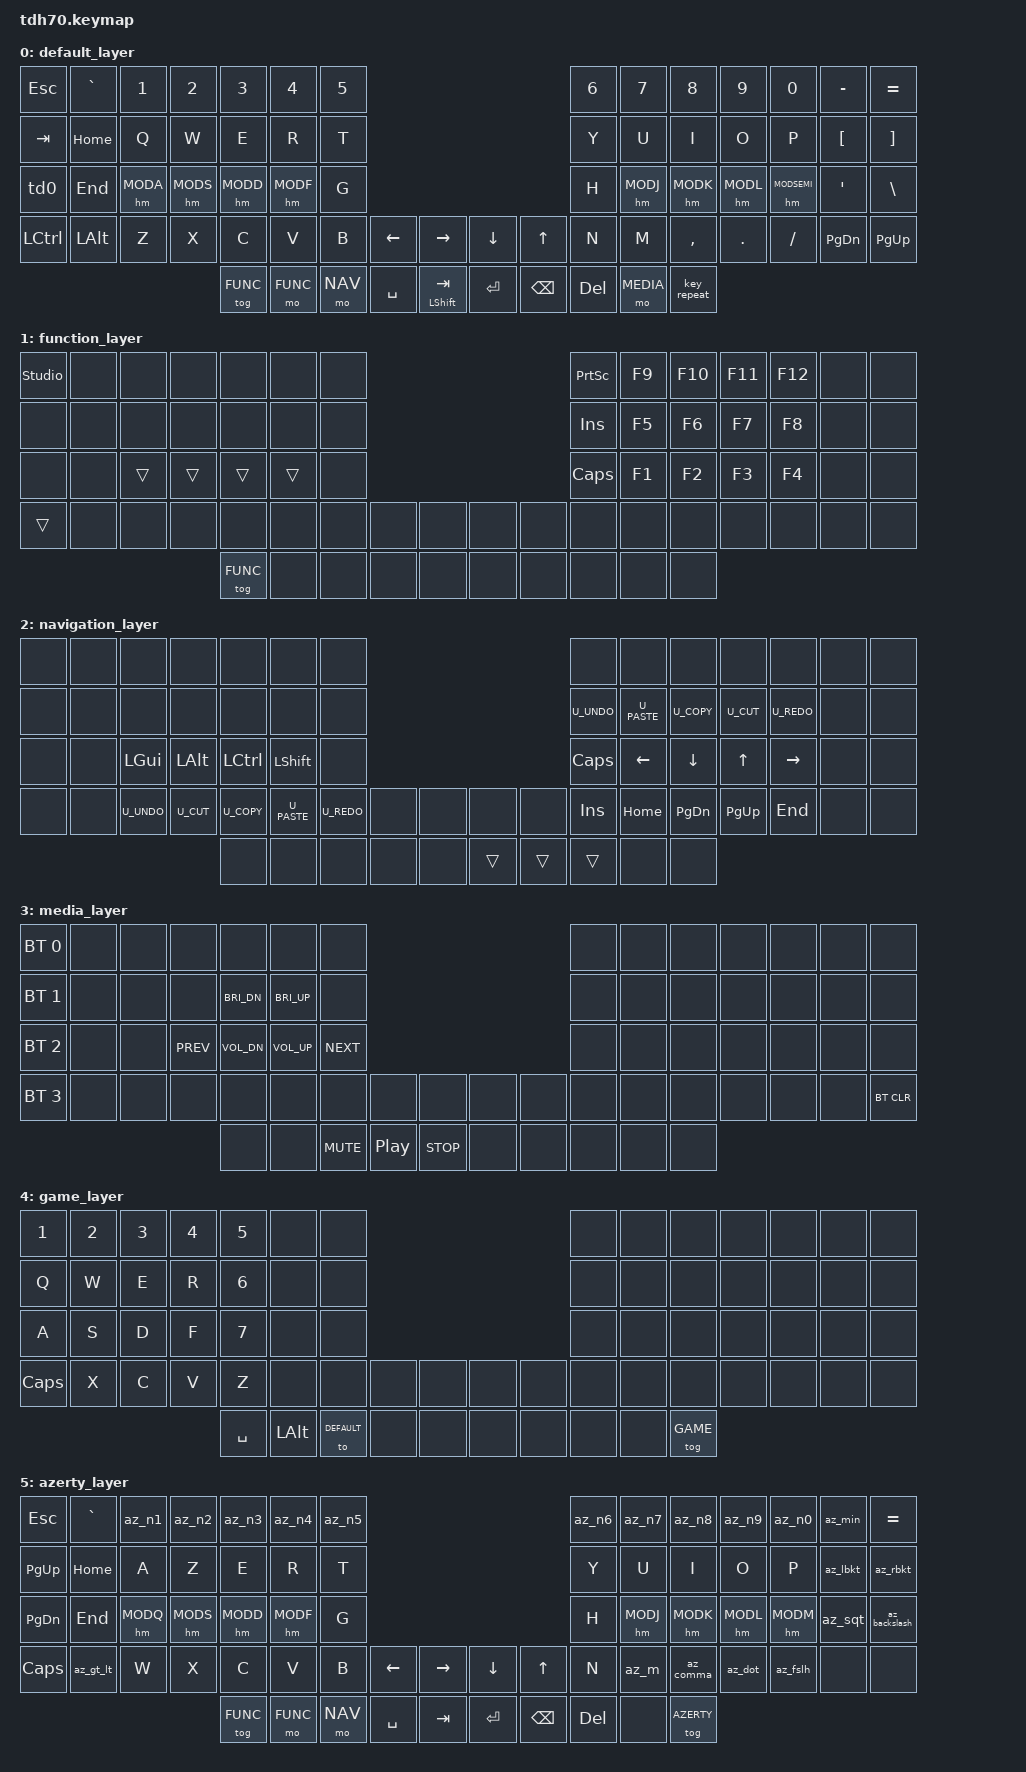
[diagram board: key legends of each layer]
/*
 * Copyright (c) 2020 The ZMK Contributors
 *
 * SPDX-License-Identifier: MIT
 */

#include <behaviors.dtsi>
#include <dt-bindings/zmk/keys.h>
#include <dt-bindings/zmk/bt.h>

#define DEFAULT 0
#define FUNC  1
#define NAV  2
#define MEDIA 3
#define GAME  4
#define AZERTY 5

#define XXX &none
#define ___ &trans

// home-row mods
#define MODA LGUI A
#define MODQ LGUI Q // AZERTY
#define MODS LALT S
#define MODD LCTRL D
#define MODF LSHIFT F

#define MODJ RSHIFT J
#define MODK RCTRL K
#define MODL RALT L
#define MODSEMI RGUI SEMI
#define MODM RGUI M // AZERTY
#define U_COPY LC(C)
#define U_PASTE LC(V)
#define U_CUT LC(X)
#define U_UNDO LC(Z)
#define U_REDO LC(Y)

/ {
    behaviors {
        td0: tap_dance_0 {
            compatible = "zmk,behavior-tap-dance";
            label = "TAP_DANCE_0";
            #binding-cells = <0>;
            tapping-term-ms = <200>;
            bindings = <&kp LSHIFT>, <&caps_word>;
        };

        hm: homerow_mods {
            compatible = "zmk,behavior-hold-tap";
            label = "HOMEROW_MODS";
            #binding-cells = <2>;
            tapping-term-ms = <200>;
            quick_tap_ms = <0>;
            flavor = "tap-preferred";
            bindings = <&kp>, <&kp>;
        };

        #include "azerty.dtsi"
    };



    keymap {
        compatible = "zmk,keymap";

        default_layer {
            bindings = <
// ╭─────────────┬─────────────┬─────────────┬─────────────┬─────────────┬──────────────┬─────────────╮                                                           ╭─────────────┬─────────────┬─────────────┬─────────────┬─────────────┬─────────────┬──────────────╮
    &kp ESC       &kp GRAVE     &kp N1        &kp N2        &kp N3        &kp N4         &kp N5                                                                    &kp N6        &kp N7        &kp N8        &kp N9        &kp N0        &kp MINUS     &kp EQUAL
// ├─────────────┼─────────────┼─────────────┼─────────────┼─────────────┼──────────────┼─────────────┤                                                           ├─────────────┼─────────────┼─────────────┼─────────────┼─────────────┼─────────────┼──────────────┤
    &kp TAB       &kp HOME      &kp Q         &kp W         &kp E         &kp R          &kp T                                                                     &kp Y         &kp U         &kp I         &kp O         &kp P         &kp LBKT      &kp RBKT
// ├─────────────┼─────────────┼─────────────┼─────────────┼─────────────┼──────────────┼─────────────┤                                                           ├─────────────┼─────────────┼─────────────┼─────────────┼─────────────┼─────────────┼──────────────┤
    &td0          &kp END       &hm MODA      &hm MODS      &hm MODD      &hm MODF       &kp G                                                                     &kp H         &hm MODJ      &hm  MODK     &hm MODL      &hm MODSEMI   &kp SQT       &kp BACKSLASH
// ├─────────────┼─────────────┼─────────────┼─────────────┼─────────────┼──────────────┼─────────────┼─────────────┬─────────────╮   ╭────────────┼──────────────┼─────────────┼─────────────┼─────────────┼─────────────┼─────────────┼─────────────┼──────────────┤
    &kp LCTRL     &kp LALT      &kp Z         &kp X         &kp C         &kp V          &kp B         &kp LEFT      &kp RIGHT         &kp DOWN       &kp UP       &kp N         &kp M         &kp COMMA     &kp DOT       &kp FSLH      &kp PG_DN     &kp PG_UP
// ╰─────────────┴─────────────┴─────────────┴─────────────┼─────────────┼──────────────┼─────────────┼─────────────┼─────────────┤   ├────────────┴──────────────┴─────────────┴─────────────┼─────────────┼─────────────┼─────────────┼─────────────┼──────────────╯
                                                            &tog FUNC     &mo FUNC       &mo NAV       &kp SPACE     &hm LSHIFT TAB    &kp RET      &kp BSPC       &kp DEL      &mo MEDIA     &key_repeat 
//                                                         ╰─────────────┴──────────────┴─────────────┴─────────────┴─────────────╯   ╰────────────┴──────────────┴─────────────┴─────────────┴─────────────╯
            >;
        };
        function_layer {
            bindings = <
// ╭─────────────┬─────────────┬─────────────┬─────────────┬─────────────┬──────────────┬─────────────╮                                                           ╭─────────────┬─────────────┬─────────────┬─────────────┬─────────────┬─────────────┬──────────────╮
    &studio_unlock           XXX           XXX           XXX           XXX           XXX            XXX                                                                       &kp PSCRN     &kp F9        &kp F10       &kp F11       &kp F12       XXX           XXX
// ├─────────────┼─────────────┼─────────────┼─────────────┼─────────────┼──────────────┼─────────────┤                                                           ├─────────────┼─────────────┼─────────────┼─────────────┼─────────────┼─────────────┼──────────────┤
    XXX           XXX           XXX           XXX           XXX           XXX            XXX                                                                       &kp INS       &kp F5        &kp F6        &kp F7        &kp F8        XXX           XXX
// ├─────────────┼─────────────┼─────────────┼─────────────┼─────────────┼──────────────┼─────────────┤                                                           ├─────────────┼─────────────┼─────────────┼─────────────┼─────────────┼─────────────┼──────────────┤
    XXX           XXX           ___           ___           ___           ___            XXX                                                                       &kp CAPS      &kp F1        &kp F2        &kp F3        &kp F4        XXX           XXX
// ├─────────────┼─────────────┼─────────────┼─────────────┼─────────────┼──────────────┼─────────────┼─────────────┬─────────────╮   ╭────────────┼──────────────┼─────────────┼─────────────┼─────────────┼─────────────┼─────────────┼─────────────┼──────────────┤
    ___           XXX           XXX           XXX           XXX           XXX            XXX           XXX           XXX               XXX           XXX           XXX           XXX           XXX           XXX           XXX           XXX           XXX
// ╰─────────────┴─────────────┴─────────────┴─────────────┼─────────────┼──────────────┼─────────────┼─────────────┼─────────────┤   ├────────────┴──────────────┴─────────────┴─────────────┼─────────────┼─────────────┼─────────────┼─────────────┼──────────────╯
                                                            &tog FUNC     XXX            XXX           XXX           XXX               XXX           XXX           XXX           XXX           XXX
//                                                         ╰─────────────┴──────────────┴─────────────┴─────────────┴─────────────╯   ╰────────────┴──────────────┴─────────────┴─────────────┴─────────────╯
            >;
        };
        navigation_layer {
            bindings = <
// ╭─────────────┬─────────────┬─────────────┬─────────────┬─────────────┬──────────────┬─────────────╮                                                           ╭─────────────┬─────────────┬─────────────┬─────────────┬─────────────┬─────────────┬──────────────╮
    XXX           XXX           XXX           XXX           XXX            XXX           XXX                                                                       XXX           XXX           XXX           XXX           XXX           XXX           XXX
// ├─────────────┼─────────────┼─────────────┼─────────────┼─────────────┼──────────────┼─────────────┤                                                           ├─────────────┼─────────────┼─────────────┼─────────────┼─────────────┼─────────────┼──────────────┤
    XXX           XXX           XXX           XXX           XXX            XXX           XXX                                                                       &kp U_UNDO    &kp U_PASTE   &kp U_COPY    &kp U_CUT     &kp U_REDO    XXX           XXX
// ├─────────────┼─────────────┼─────────────┼─────────────┼─────────────┼──────────────┼─────────────┤                                                           ├─────────────┼─────────────┼─────────────┼─────────────┼─────────────┼─────────────┼──────────────┤
    XXX           XXX           &kp LGUI      &kp LALT      &kp LCTRL     &kp LSHIFT     XXX                                                                       &kp CAPS      &kp LEFT      &kp DOWN      &kp UP        &kp RIGHT     XXX           XXX
// ├─────────────┼─────────────┼─────────────┼─────────────┼─────────────┼──────────────┼─────────────┼─────────────┬─────────────╮   ╭────────────┼──────────────┼─────────────┼─────────────┼─────────────┼─────────────┼─────────────┼─────────────┼──────────────┤
    XXX           XXX           &kp U_UNDO    &kp U_CUT     &kp U_COPY    &kp U_PASTE    &kp U_REDO    XXX           XXX               XXX           XXX           &kp INS       &kp HOME      &kp PG_DN     &kp PG_UP     &kp END       XXX           XXX
// ╰─────────────┴─────────────┴─────────────┴─────────────┼─────────────┼──────────────┼─────────────┼─────────────┼─────────────┤   ├────────────┴──────────────┴─────────────┴─────────────┼─────────────┼─────────────┼─────────────┼─────────────┼──────────────╯
                                                            XXX           XXX            XXX           XXX           XXX               ___          ___            ___           XXX           XXX
//                                                         ╰─────────────┴──────────────┴─────────────┴─────────────┴─────────────╯   ╰────────────┴──────────────┴─────────────┴─────────────┴─────────────╯
            >;
        };
        media_layer {
            bindings = <
// ╭─────────────┬─────────────┬─────────────┬─────────────┬─────────────┬─────────────┬─────────────╮                                                           ╭─────────────┬─────────────┬─────────────┬─────────────┬─────────────┬─────────────┬──────────────╮
    &bt BT_SEL 0  XXX           XXX           XXX           XXX           XXX           XXX                                                                       XXX           XXX           XXX           XXX           XXX           XXX           XXX
// ├─────────────┼─────────────┼─────────────┼─────────────┼─────────────┼─────────────┼─────────────┤                                                           ├─────────────┼─────────────┼─────────────┼─────────────┼─────────────┼─────────────┼──────────────┤
    &bt BT_SEL 1  XXX           XXX           XXX           &kp C_BRI_DN  &kp C_BRI_UP  XXX                                                                       XXX           XXX           XXX           XXX           XXX           XXX           XXX
// ├─────────────┼─────────────┼─────────────┼─────────────┼─────────────┼─────────────┼─────────────┤                                                           ├─────────────┼─────────────┼─────────────┼─────────────┼─────────────┼─────────────┼──────────────┤
    &bt BT_SEL 2  XXX           XXX           &kp C_PREV    &kp C_VOL_DN  &kp C_VOL_UP  &kp C_NEXT                                                                XXX           XXX           XXX           XXX           XXX           XXX           XXX
// ├─────────────┼─────────────┼─────────────┼─────────────┼─────────────┼─────────────┼─────────────┼─────────────┬─────────────╮   ╭────────────┼──────────────┼─────────────┼─────────────┼─────────────┼─────────────┼─────────────┼─────────────┼──────────────┤
    &bt BT_SEL 3  XXX           XXX           XXX           XXX           XXX           XXX           XXX           XXX               XXX           XXX           XXX           XXX           XXX           XXX           XXX           XXX           &bt BT_CLR
// ╰─────────────┴─────────────┴─────────────┴─────────────┼─────────────┼─────────────┼─────────────┼─────────────┼─────────────┤   ├────────────┴──────────────┴─────────────┴─────────────┼─────────────┼─────────────┼─────────────┼─────────────┼──────────────╯
                                                            XXX           XXX           &kp C_MUTE    &kp C_PP      &kp C_STOP        XXX           XXX           XXX           XXX           XXX
//                                                         ╰─────────────┴─────────────┴─────────────┴─────────────┴─────────────╯   ╰────────────┴──────────────┴─────────────┴─────────────┴─────────────╯
            >;
        };
        game_layer {
            bindings = <
// ╭─────────────┬─────────────┬─────────────┬─────────────┬─────────────┬──────────────┬─────────────╮                                                           ╭─────────────┬─────────────┬─────────────┬─────────────┬─────────────┬─────────────┬──────────────╮
    &kp N1        &kp N2        &kp N3        &kp N4        &kp N5        XXX            XXX                                                                       XXX           XXX           XXX           XXX           XXX            XXX           XXX
// ├─────────────┼─────────────┼─────────────┼─────────────┼─────────────┼──────────────┼─────────────┤                                                           ├─────────────┼─────────────┼─────────────┼─────────────┼─────────────┼─────────────┼──────────────┤
    &kp Q         &kp W         &kp E         &kp R         &kp N6        XXX            XXX                                                                       XXX           XXX           XXX           XXX           XXX            XXX           XXX
// ├─────────────┼─────────────┼─────────────┼─────────────┼─────────────┼──────────────┼─────────────┤                                                           ├─────────────┼─────────────┼─────────────┼─────────────┼─────────────┼─────────────┼──────────────┤
    &kp A         &kp S         &kp D         &kp F         &kp N7        XXX            XXX                                                                       XXX           XXX           XXX           XXX           XXX            XXX           XXX
// ├─────────────┼─────────────┼─────────────┼─────────────┼─────────────┼──────────────┼─────────────┼─────────────┬─────────────╮   ╭────────────┼──────────────┼─────────────┼─────────────┼─────────────┼─────────────┼─────────────┼─────────────┼──────────────┤
    &kp CAPS      &kp X         &kp C         &kp V         &kp Z         XXX            XXX           XXX           XXX               XXX           XXX           XXX           XXX           XXX           XXX           XXX            XXX           XXX
// ╰─────────────┴─────────────┴─────────────┴─────────────┼─────────────┼──────────────┼─────────────┼─────────────┼─────────────┤   ├────────────┴──────────────┴─────────────┴─────────────┼─────────────┼─────────────┼─────────────┼─────────────┼──────────────╯
                                                            &kp SPACE     &kp LALT       &to DEFAULT   XXX           XXX               XXX           XXX           XXX           XXX           &tog GAME
//                                                         ╰─────────────┴──────────────┴─────────────┴─────────────┴─────────────╯   ╰────────────┴──────────────┴─────────────┴─────────────┴─────────────╯
            >;
        };
        azerty_layer {
            bindings = <
// ╭─────────────┬─────────────┬─────────────┬─────────────┬─────────────┬──────────────┬─────────────╮                                                           ╭─────────────┬─────────────┬─────────────┬─────────────┬─────────────┬─────────────┬──────────────╮
    &kp ESC       &kp GRAVE     &az_n1        &az_n2        &az_n3        &az_n4         &az_n5                                                                    &az_n6        &az_n7        &az_n8        &az_n9        &az_n0        &az_min       &kp EQUAL
// ├─────────────┼─────────────┼─────────────┼─────────────┼─────────────┼──────────────┼─────────────┤                                                           ├─────────────┼─────────────┼─────────────┼─────────────┼─────────────┼─────────────┼──────────────┤
    &kp PG_UP     &kp HOME      &kp A         &kp Z         &kp E         &kp R          &kp T                                                                     &kp Y         &kp U         &kp I         &kp O         &kp P         &az_lbkt      &az_rbkt
// ├─────────────┼─────────────┼─────────────┼─────────────┼─────────────┼──────────────┼─────────────┤                                                           ├─────────────┼─────────────┼─────────────┼─────────────┼─────────────┼─────────────┼──────────────┤
    &kp PG_DN     &kp END       &hm MODQ      &hm MODS      &hm MODD      &hm MODF       &kp G                                                                     &kp H         &hm MODJ      &hm  MODK     &hm MODL      &hm MODM      &az_sqt       &az_backslash
// ├─────────────┼─────────────┼─────────────┼─────────────┼─────────────┼──────────────┼─────────────┼─────────────┬─────────────╮   ╭────────────┼──────────────┼─────────────┼─────────────┼─────────────┼─────────────┼─────────────┼─────────────┼──────────────┤
    &kp CAPS      &az_gt_lt     &kp W         &kp X         &kp C         &kp V          &kp B         &kp LEFT      &kp RIGHT         &kp DOWN       &kp UP      &kp N         &az_m         &az_comma     &az_dot       &az_fslh      XXX           XXX
// ╰─────────────┴─────────────┴─────────────┴─────────────┼─────────────┼──────────────┼─────────────┼─────────────┼─────────────┤   ├────────────┴──────────────┴─────────────┴─────────────┼─────────────┼─────────────┼─────────────┼─────────────┼──────────────╯
                                                            &tog FUNC     &mo FUNC       &mo NAV       &kp SPACE     &kp TAB           &kp RET      &kp BSPC       &kp DEL       XXX           &tog AZERTY
//                                                         ╰─────────────┴──────────────┴─────────────┴─────────────┴─────────────╯   ╰────────────┴──────────────┴─────────────┴─────────────┴─────────────╯
            >;
        };
        studio_layer_1 {
            status = "reserved";
        };

        studio_layer_2 {
            status = "reserved";
        };
    };
};
